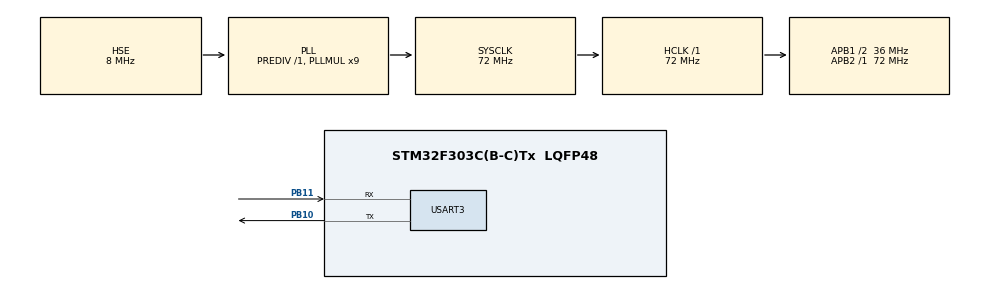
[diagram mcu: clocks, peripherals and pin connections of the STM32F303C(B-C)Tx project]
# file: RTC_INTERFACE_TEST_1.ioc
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Mcu.Family=STM32F3
Mcu.Name=STM32F303C(B-C)Tx
Mcu.Package=LQFP48
NVIC.PriorityGroup=NVIC_PRIORITYGROUP_4
PA13.Mode=Serial_Wire
PA13.Signal=SYS_JTMS-SWDIO
PA14.Mode=Serial_Wire
PA14.Signal=SYS_JTCK-SWCLK
PB10.Mode=Asynchronous
PB10.Signal=USART3_TX
PB11.Mode=Asynchronous
PB11.Signal=USART3_RX
PC14-OSC32_IN.Mode=LSE-External-Oscillator
PC14-OSC32_IN.Signal=RCC_OSC32_IN
PC15-OSC32_OUT.Mode=LSE-External-Oscillator
PC15-OSC32_OUT.Signal=RCC_OSC32_OUT
PF0-OSC_IN.Mode=HSE-External-Oscillator
PF0-OSC_IN.Signal=RCC_OSC_IN
PF1-OSC_OUT.Mode=HSE-External-Oscillator
PF1-OSC_OUT.Signal=RCC_OSC_OUT
ProjectManager.HeapSize=0x200
ProjectManager.StackSize=0x400
ProjectManager.TargetToolchain=STM32CubeIDE
RCC.AHBFreq_Value=72000000
RCC.APB1CLKDivider=RCC_HCLK_DIV2
RCC.APB1Freq_Value=36000000
RCC.APB1TimFreq_Value=72000000
RCC.APB2Freq_Value=72000000
RCC.APB2TimFreq_Value=72000000
RCC.CortexFreq_Value=72000000
RCC.HCLKFreq_Value=72000000
RCC.HSE_VALUE=8000000
RCC.HSI_VALUE=8000000
RCC.PLLMUL=RCC_PLL_MUL9
RCC.PLLSourceVirtual=RCC_PLLSOURCE_HSE
RCC.SYSCLKFreq_VALUE=72000000
RCC.SYSCLKSourceVirtual=RCC_SYSCLKSOURCE_PLLCLK
RCC.USBFreq_Value=72000000
RTC.Date=16
RTC.Month=RTC_MONTH_MARCH
RTC.Year=21
USART3.VirtualMode-Asynchronous=VM_ASYNC
VP_RTC_VS_RTC_Activate.Mode=RTC_Enabled
VP_RTC_VS_RTC_Calendar.Mode=RTC_Calendar
board=custom

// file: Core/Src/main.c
/* USER CODE BEGIN Header */
/**
  ******************************************************************************
  * @file           : main.c
  * @brief          : Main program body
  ******************************************************************************
  * @attention
  *
  * <h2><center>&copy; Copyright (c) 2021 STMicroelectronics.
  * All rights reserved.</center></h2>
  *
  * This software component is licensed by ST under BSD 3-Clause license,
  * the "License"; You may not use this file except in compliance with the
  * License. You may obtain a copy of the License at:
  *                        opensource.org/licenses/BSD-3-Clause
  *
  ******************************************************************************
  */
/* USER CODE END Header */

#include "main.h"

/* USER CODE BEGIN Includes */
#include <stdio.h>
#include <string.h>
/* USER CODE END Includes */

/* USER CODE BEGIN PTD */
char time[30];
char date[30];
/* USER CODE END PTD */
RTC_TimeTypeDef sTime;
 RTC_DateTypeDef sDate;

RTC_HandleTypeDef hrtc;

UART_HandleTypeDef huart3;

void SystemClock_Config(void);
static void MX_GPIO_Init(void);
static void MX_RTC_Init(void);
static void MX_USART3_UART_Init(void);

int main(void)
{

  /* MCU Configuration--------------------------------------------------------*/

  /* Reset of all peripherals, Initializes the Flash interface and the Systick. */
  HAL_Init();

  /* Configure the system clock */
  SystemClock_Config();

  /* Initialize all configured peripherals */
  MX_GPIO_Init();
  MX_RTC_Init();
  MX_USART3_UART_Init();

  /* Infinite loop */
  while (1)
  {
HAL_RTC_GetTime(&hrtc, &sTime, RTC_FORMAT_BIN);
HAL_RTC_GetDate(&hrtc, &sDate, RTC_FORMAT_BIN);

sprintf(date,"Date: %02d.%02d.%02d\t",sDate.Date,sDate.Month,sDate.Year);
sprintf(time,"Time: %02d.%02d.%02d\r\n",sTime.Hours,sTime.Minutes,sTime.Seconds);

HAL_UART_Transmit(&huart3, (uint8_t *)date, sizeof(date), 300);
HAL_UART_Transmit(&huart3, (uint8_t *)time, sizeof(time), 300);
HAL_Delay(1000);
  }
  /* USER CODE END 3 */
}

void SystemClock_Config(void)
{
  RCC_OscInitTypeDef RCC_OscInitStruct = {0};
  RCC_ClkInitTypeDef RCC_ClkInitStruct = {0};
  RCC_PeriphCLKInitTypeDef PeriphClkInit = {0};

  /** Initializes the CPU, AHB and APB busses clocks
  */
  RCC_OscInitStruct.OscillatorType = RCC_OSCILLATORTYPE_LSI|RCC_OSCILLATORTYPE_HSE;
  RCC_OscInitStruct.HSEState = RCC_HSE_ON;
  RCC_OscInitStruct.HSEPredivValue = RCC_HSE_PREDIV_DIV1;
  RCC_OscInitStruct.HSIState = RCC_HSI_ON;
  RCC_OscInitStruct.LSIState = RCC_LSI_ON;
  RCC_OscInitStruct.PLL.PLLState = RCC_PLL_ON;
  RCC_OscInitStruct.PLL.PLLSource = RCC_PLLSOURCE_HSE;
  RCC_OscInitStruct.PLL.PLLMUL = RCC_PLL_MUL9;
  if (HAL_RCC_OscConfig(&RCC_OscInitStruct) != HAL_OK)
  {
    Error_Handler();
  }
  /** Initializes the CPU, AHB and APB busses clocks
  */
  RCC_ClkInitStruct.ClockType = RCC_CLOCKTYPE_HCLK|RCC_CLOCKTYPE_SYSCLK
                              |RCC_CLOCKTYPE_PCLK1|RCC_CLOCKTYPE_PCLK2;
  RCC_ClkInitStruct.SYSCLKSource = RCC_SYSCLKSOURCE_PLLCLK;
  RCC_ClkInitStruct.AHBCLKDivider = RCC_SYSCLK_DIV1;
  RCC_ClkInitStruct.APB1CLKDivider = RCC_HCLK_DIV2;
  RCC_ClkInitStruct.APB2CLKDivider = RCC_HCLK_DIV1;

  if (HAL_RCC_ClockConfig(&RCC_ClkInitStruct, FLASH_LATENCY_2) != HAL_OK)
  {
    Error_Handler();
  }
  PeriphClkInit.PeriphClockSelection = RCC_PERIPHCLK_USART3|RCC_PERIPHCLK_RTC;
  PeriphClkInit.Usart3ClockSelection = RCC_USART3CLKSOURCE_PCLK1;
  PeriphClkInit.RTCClockSelection = RCC_RTCCLKSOURCE_LSI;
  if (HAL_RCCEx_PeriphCLKConfig(&PeriphClkInit) != HAL_OK)
  {
    Error_Handler();
  }
}

static void MX_RTC_Init(void)
{

  RTC_TimeTypeDef sTime = {0};
  RTC_DateTypeDef sDate = {0};

  /** Initialize RTC Only
  */
  hrtc.Instance = RTC;
  hrtc.Init.HourFormat = RTC_HOURFORMAT_24;
  hrtc.Init.AsynchPrediv = 127;
  hrtc.Init.SynchPrediv = 255;
  hrtc.Init.OutPut = RTC_OUTPUT_DISABLE;
  hrtc.Init.OutPutPolarity = RTC_OUTPUT_POLARITY_HIGH;
  hrtc.Init.OutPutType = RTC_OUTPUT_TYPE_OPENDRAIN;
  if (HAL_RTC_Init(&hrtc) != HAL_OK)
  {
    Error_Handler();
  }

  /** Initialize RTC and set the Time and Date
  */
  sTime.Hours = 0x10;
  sTime.Minutes = 0x20;
  sTime.Seconds = 0x30;
  sTime.DayLightSaving = RTC_DAYLIGHTSAVING_NONE;
  sTime.StoreOperation = RTC_STOREOPERATION_RESET;
  if (HAL_RTC_SetTime(&hrtc, &sTime, RTC_FORMAT_BCD) != HAL_OK)
  {
    Error_Handler();
  }
  sDate.WeekDay = RTC_WEEKDAY_MONDAY;
  sDate.Month = RTC_MONTH_MARCH;
  sDate.Date = 0x16;
  sDate.Year = 0x21;

  if (HAL_RTC_SetDate(&hrtc, &sDate, RTC_FORMAT_BCD) != HAL_OK)
  {
    Error_Handler();
  }

}

static void MX_USART3_UART_Init(void)
{

  huart3.Instance = USART3;
  huart3.Init.BaudRate = 9600;
  huart3.Init.WordLength = UART_WORDLENGTH_8B;
  huart3.Init.StopBits = UART_STOPBITS_1;
  huart3.Init.Parity = UART_PARITY_NONE;
  huart3.Init.Mode = UART_MODE_TX_RX;
  huart3.Init.HwFlowCtl = UART_HWCONTROL_NONE;
  huart3.Init.OverSampling = UART_OVERSAMPLING_16;
  huart3.Init.OneBitSampling = UART_ONE_BIT_SAMPLE_DISABLE;
  huart3.AdvancedInit.AdvFeatureInit = UART_ADVFEATURE_NO_INIT;
  if (HAL_UART_Init(&huart3) != HAL_OK)
  {
    Error_Handler();
  }

}

static void MX_GPIO_Init(void)
{

  /* GPIO Ports Clock Enable */
  __HAL_RCC_GPIOC_CLK_ENABLE();
  __HAL_RCC_GPIOF_CLK_ENABLE();
  __HAL_RCC_GPIOB_CLK_ENABLE();
  __HAL_RCC_GPIOA_CLK_ENABLE();

}

void Error_Handler(void)
{
}

/************************ (C) COPYRIGHT STMicroelectronics *****END OF FILE****/
